# SH30F2xx register map
Vendor: Sino Wealth Electronic Ltd.; Series: SH30Fxxx; File version: 1.0
Sinowealth 32-bit Cortex-M0+ Microcontroller based device.
CPU: CM0+ r0p1, little endian, no MPU, no FPU, 2 interrupt priority bits
Registers are 32-bit, read-write, reset 0x0 unless marked. A register's access mark holds for its fields unless they carry their own. Offsets are from the block's base; lines under a group give offsets from that group; [hi:lo] are bit positions; {n}, {i} and the like mark numbered series; 'fields as' and 'values as' point back to an identical list; <NAME> marks a mode.

## Memory map
0x40000400 PCA0 size 0x44
0x40000C00 TIM7 size 0x14
0x40001000 TIM8 size 0x14
0x40001800 UART0 size 0x1C
0x40001C00 UART1 size 0x1C
0x40002400 SPI0 size 0x10
0x40003000 IWDT size 0x8
0x40003400 WWDT size 0x10
0x40003800 AMOC size 0x14
0x40004000 EXTI size 0x28
0x40005000 PWM3 size 0x1C
0x40005400 PWM4 size 0x1C
0x40040000 GPIOA size 0x30
0x40040080 GPIOB size 0x30
0x40040100 GPIOC size 0x30
0x40040400 MCM size 0x8C
0x40040800 SYSCFG size 0x84
0x40040C00 RCC size 0x3C
0x40041000 FLASH size 0x214
0x40041400 MACP size 0x120
0x40041800 ADC size 0x6C

## Interrupts
0 WWDT
1 BOD (SYSCFG)
2 RCC
3 EXTI0 (EXTI)
4 EXTI1 (EXTI)
5 EXTI2 (EXTI)
6 EXTI3 (EXTI)
7 MCM_FLT (MCM)
8 MCM_PWM (MCM)
9 ADC
10 PCA0
12 PCA0_FLT (PCA0)
13 CMP2 (AMOC)
14 CMP0 (AMOC)
15 CMP1 (AMOC)
16 EXTI4 (EXTI)
17 EXTI5 (EXTI)
18 PWM3
19 SPI0
20 UART0
21 UART1
22 PWM4
23 TIM7
24 TIM8
25 EXTI6_7 (EXTI)

## PCA0
Base 0x40000400
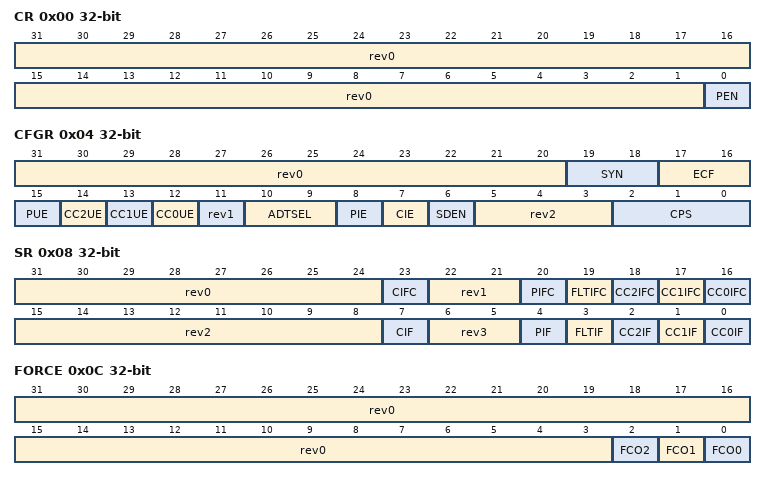
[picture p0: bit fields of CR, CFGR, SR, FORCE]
0x00 CR
  [31:1] rev0, [0] PEN
0x04 CFGR
  [31:20] rev0, [19:18] SYN, [17:16] ECF, [15] PUE, [14] CC2UE, [13] CC1UE, [12] CC0UE, [11] rev1, [10:9] ADTSEL, [8] PIE, [7] CIE, [6] SDEN, [5:3] rev2, [2:0] CPS
0x08 SR
  [31:24] rev0, [23] CIFC, [22:21] rev1, [20] PIFC, [19] FLTIFC, [18] CC2IFC, [17] CC1IFC, [16] CC0IFC, [15:8] rev2, [7] CIF ro, [6:5] rev3, [4] PIF ro, [3] FLTIF ro, [2] CC2IF ro, [1] CC1IF ro, [0] CC0IF ro
0x0C FORCE
  [31:3] rev0, [2] FCO2, [1] FCO1, [0] FCO0
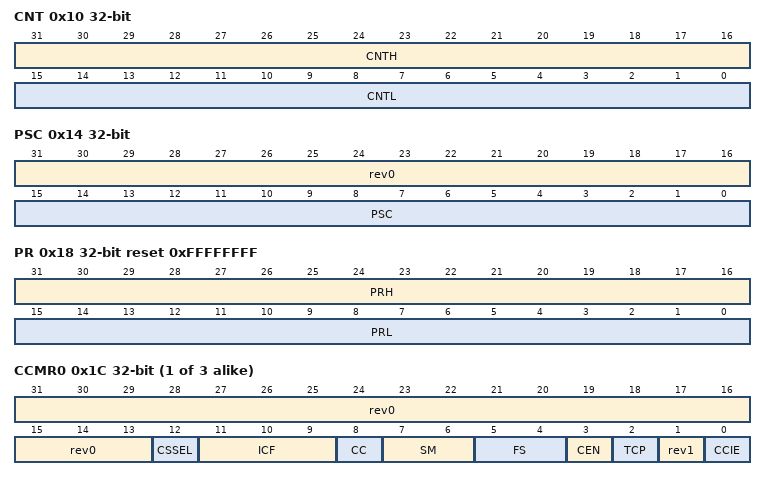
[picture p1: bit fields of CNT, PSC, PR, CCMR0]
0x10 CNT
  [31:16] CNTH, [15:0] CNTL
0x14 PSC
  [31:16] rev0, [15:0] PSC
0x18 PR reset 0xFFFFFFFF
  [31:16] PRH, [15:0] PRL
{0x1C+4i} CCMR{i} (i=0..2)
  [31:13] rev0, [12] CSSEL, [11:9] ICF, [8] CC, [7:6] SM, [5:4] FS, [3] CEN, [2] TCP, [1] rev1, [0] CCIE
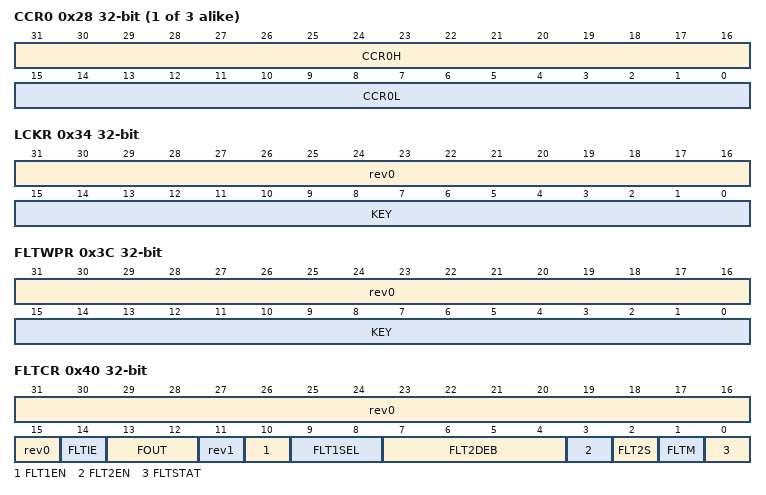
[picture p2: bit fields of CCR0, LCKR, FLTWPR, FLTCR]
{0x28+4i} CCR{i} (i=0..2)
  [31:16] CCR{i}H, [15:0] CCR{i}L
0x34 LCKR
  [31:16] rev0, [15:0] KEY
0x38 ADTR
0x3C FLTWPR
  [31:16] rev0, [15:0] KEY
0x40 FLTCR
  [31:15] rev0, [14] FLTIE, [13:12] FOUT, [11] rev1, [10] FLT1EN, [9:8] FLT1SEL, [7:4] FLT2DEB, [3] FLT2EN, [2] FLT2S, [1] FLTM, [0] FLTSTAT

## TIM7
Base 0x40000C00
Same registers: TIM8 0x40001000
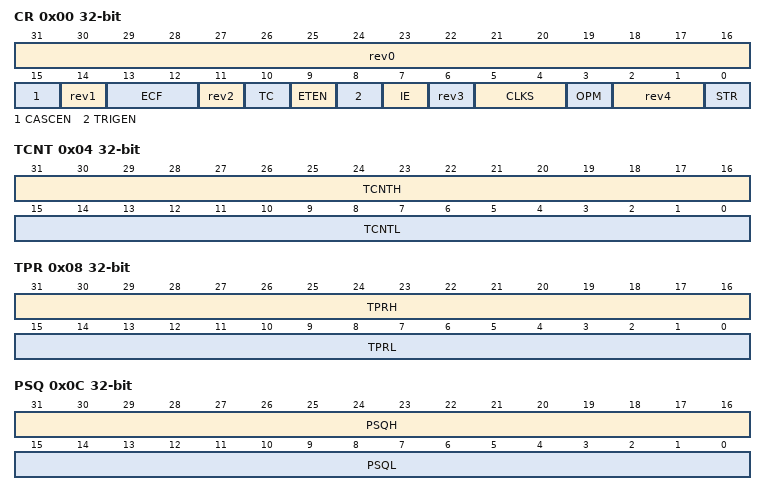
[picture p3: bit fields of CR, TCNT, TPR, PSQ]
0x00 CR
  [31:16] rev0, [15] CASCEN, [14] rev1, [13:12] ECF, [11] rev2, [10] TC, [9] ETEN, [8] TRIGEN, [7] IE, [6] rev3, [5:4] CLKS, [3] OPM, [2:1] rev4, [0] STR
0x04 TCNT
  [31:16] TCNTH, [15:0] TCNTL
0x08 TPR
  [31:16] TPRH, [15:0] TPRL
0x0C PSQ
  [31:16] PSQH, [15:0] PSQL
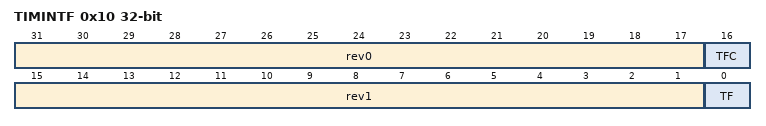
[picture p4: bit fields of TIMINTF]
0x10 TIMINTF
  [31:17] rev0, [16] TFC, [15:1] rev1, [0] TF ro

## UART0
Base 0x40001800
Same registers: UART1 0x40001C00
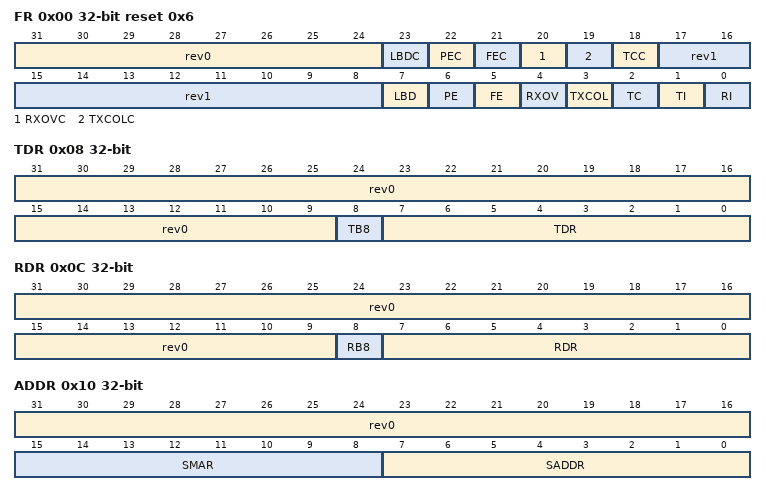
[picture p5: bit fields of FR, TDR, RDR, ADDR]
0x00 FR reset 0x6
  [31:24] rev0, [23] LBDC, [22] PEC, [21] FEC, [20] RXOVC, [19] TXCOLC, [18] TCC, [17:8] rev1, [7] LBD ro, [6] PE ro, [5] FE ro, [4] RXOV ro, [3] TXCOL ro, [2] TC ro, [1] TI ro, [0] RI ro
0x08 TDR
  [31:9] rev0, [8] TB8, [7:0] TDR
0x0C RDR ro
  [31:9] rev0 rw, [8] RB8, [7:0] RDR
0x10 ADDR
  [31:16] rev0, [15:8] SMAR, [7:0] SADDR
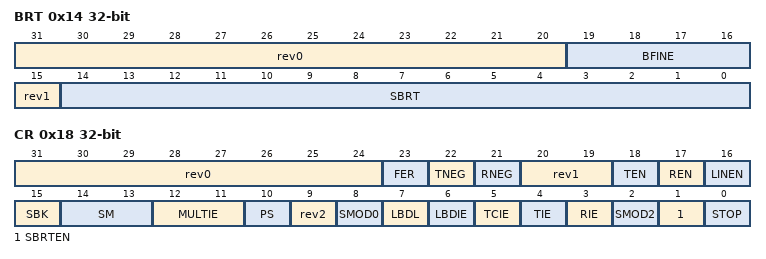
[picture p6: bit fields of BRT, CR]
0x14 BRT
  [31:20] rev0, [19:16] BFINE, [15] rev1, [14:0] SBRT
0x18 CR
  [31:24] rev0, [23] FER, [22] TNEG, [21] RNEG, [20:19] rev1, [18] TEN, [17] REN, [16] LINEN, [15] SBK, [14:13] SM, [12:11] MULTIE, [10] PS, [9] rev2, [8] SMOD0, [7] LBDL, [6] LBDIE, [5] TCIE, [4] TIE, [3] RIE, [2] SMOD2, [1] SBRTEN, [0] STOP

## SPI0
Base 0x40002400
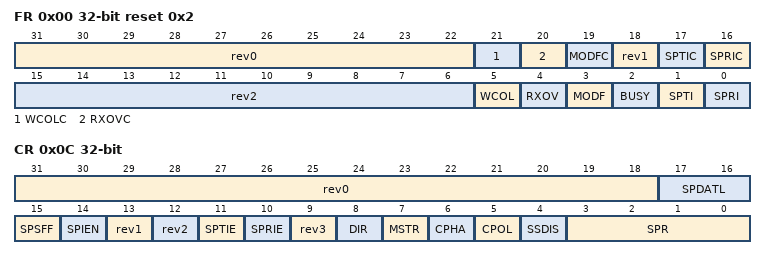
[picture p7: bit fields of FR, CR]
0x00 FR reset 0x2
  [31:22] rev0, [21] WCOLC, [20] RXOVC, [19] MODFC, [18] rev1, [17] SPTIC, [16] SPRIC, [15:6] rev2, [5] WCOL ro, [4] RXOV ro, [3] MODF ro, [2] BUSY ro, [1] SPTI ro, [0] SPRI ro
0x04 TDR
0x08 RDR ro
0x0C CR
  [31:18] rev0, [17:16] SPDATL, [15] SPSFF, [14] SPIEN, [13] rev1, [12] rev2, [11] SPTIE, [10] SPRIE, [9] rev3, [8] DIR, [7] MSTR, [6] CPHA, [5] CPOL, [4] SSDIS, [3:0] SPR
